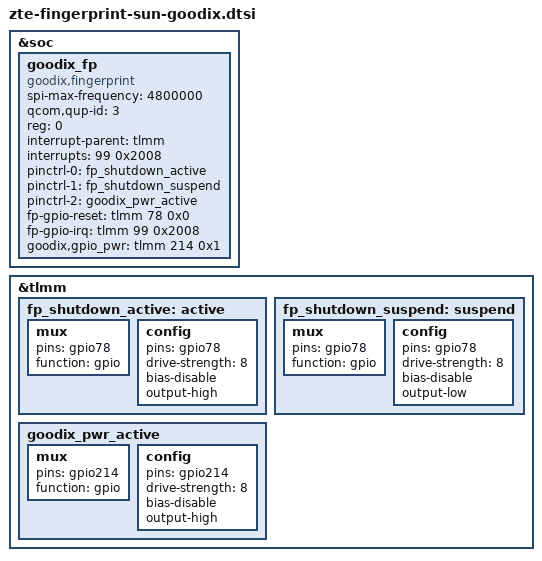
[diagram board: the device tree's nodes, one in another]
&soc {
	goodix_fp {
		status = "ok";
		compatible = "goodix,fingerprint";
		spi-max-frequency = <4800000>;
		qcom,qup-id = <3>;
		reg = <0>;

		interrupt-parent = <&tlmm>;
		interrupts = <99 0x2008>;
		pinctrl-names = "goodix_active", "goodix_suspend", "pwr_active";
		pinctrl-0 = <&fp_shutdown_active>;
		pinctrl-1 = <&fp_shutdown_suspend>;
		pinctrl-2 = <&goodix_pwr_active>;

		fp-gpio-reset = <&tlmm 78 0x0>;
		fp-gpio-irq = <&tlmm 99 0x2008>;
		goodix,gpio_pwr = <&tlmm 214 0x1>;
		interrupt-names = "goodix_wake_up";
	};
};

&tlmm {
	fp_shutdown_active:active{
		mux{
			pins = "gpio78";
			function = "gpio";
		};
		config{
			pins = "gpio78";
			drive-strength = <8>;
			bias-disable;
			output-high;
		};
	};

	fp_shutdown_suspend:suspend{
		mux{
			pins = "gpio78";
			function = "gpio";
		};
		config{
			pins = "gpio78";
			drive-strength = <8>;
			bias-disable;
			output-low;
		};
	};

	goodix_pwr_active: goodix_pwr_active {
		mux{
			pins = "gpio214";
			function = "gpio";
		};
			config {
			pins = "gpio214";
			drive-strength = <8>;
			bias-disable;
			output-high;
		};
	};
};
